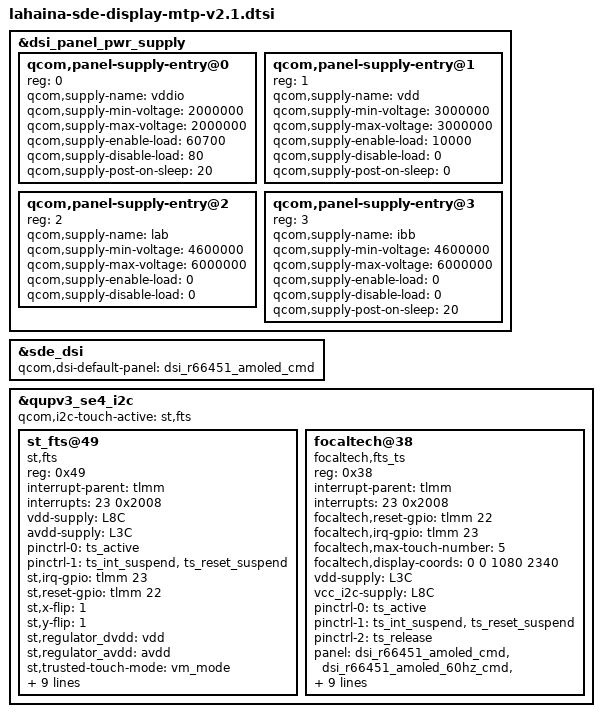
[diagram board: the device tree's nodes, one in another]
/*
 *Copyright (c) Qualcomm Technologies, Inc. and/or its subsidiaries.
 *SPDX-License-Identifier: BSD-3-Clause
*/

&dsi_panel_pwr_supply {
	#address-cells = <1>;
	#size-cells = <0>;

	qcom,panel-supply-entry@0 {
		reg = <0>;
		qcom,supply-name = "vddio";
		qcom,supply-min-voltage = <2000000>;
		qcom,supply-max-voltage = <2000000>;
		qcom,supply-enable-load = <60700>;
		qcom,supply-disable-load = <80>;
		qcom,supply-post-on-sleep = <20>;
	};

	qcom,panel-supply-entry@1 {
		reg = <1>;
		qcom,supply-name = "vdd";
		qcom,supply-min-voltage = <3000000>;
		qcom,supply-max-voltage = <3000000>;
		qcom,supply-enable-load = <10000>;
		qcom,supply-disable-load = <0>;
		qcom,supply-post-on-sleep = <0>;
	};

	qcom,panel-supply-entry@2 {
		reg = <2>;
		qcom,supply-name = "lab";
		qcom,supply-min-voltage = <4600000>;
		qcom,supply-max-voltage = <6000000>;
		qcom,supply-enable-load = <0>;
		qcom,supply-disable-load = <0>;
	};

	qcom,panel-supply-entry@3 {
		reg = <3>;
		qcom,supply-name = "ibb";
		qcom,supply-min-voltage = <4600000>;
		qcom,supply-max-voltage = <6000000>;
		qcom,supply-enable-load = <0>;
		qcom,supply-disable-load = <0>;
		qcom,supply-post-on-sleep = <20>;
	};
};

&sde_dsi {
	qcom,dsi-default-panel = <&dsi_r66451_amoled_cmd>;
};

&qupv3_se4_i2c {
	#address-cells = <1>;
	#size-cells = <0>;

	status = "ok";
	qcom,i2c-touch-active = "st,fts";

	st_fts@49 {
		compatible = "st,fts";
		reg = <0x49>;
		interrupt-parent = <&tlmm>;
		interrupts = <23 0x2008>;
		vdd-supply = <&L8C>;
		avdd-supply = <&L3C>;
		pinctrl-names = "pmx_ts_active", "pmx_ts_suspend";
		pinctrl-0 = <&ts_active>;
		pinctrl-1 = <&ts_int_suspend &ts_reset_suspend>;
		st,irq-gpio = <&tlmm 23 0x2008>;
		st,reset-gpio = <&tlmm 22 0x00>;
		st,x-flip = <1>;
		st,y-flip = <1>;
		st,regulator_dvdd = "vdd";
		st,regulator_avdd = "avdd";
		st,trusted-touch-mode = "vm_mode";
		st,touch-environment = "pvm";
		st,trusted-touch-spi-irq = <566>;
		st,trusted-touch-io-bases = <0xF114000 0xF115000 0xF116000 0xF117000 0x990000 0x00910000>;
		st,trusted-touch-io-sizes = <0x1000 0x1000 0x1000 0x1000 0x1000 0x4000>;
		panel = <&dsi_sw43404_amoled_cmd &dsi_sw43404_amoled_video
			 &dsi_sw43404_amoled_fhd_plus_cmd>;
	};

	focaltech@38 {
		compatible = "focaltech,fts_ts";
		reg = <0x38>;
		interrupt-parent = <&tlmm>;
		interrupts = <23 0x2008>;
		focaltech,reset-gpio = <&tlmm 22 0x00>;
		focaltech,irq-gpio = <&tlmm 23 0x2008>;
		focaltech,max-touch-number = <5>;
		focaltech,display-coords = <0 0 1080 2340>;

		vdd-supply = <&L3C>;
		vcc_i2c-supply = <&L8C>;

		pinctrl-names = "pmx_ts_active", "pmx_ts_suspend","pmx_ts_release";
		pinctrl-0 = <&ts_active>;
		pinctrl-1 = <&ts_int_suspend &ts_reset_suspend>;
		pinctrl-2 = <&ts_release>;

		panel = <&dsi_r66451_amoled_cmd
			 &dsi_r66451_amoled_60hz_cmd
			 &dsi_r66451_amoled_video &dsi_r66451_amoled_144hz_cmd>;

		focaltech,trusted-touch-mode = "vm_mode";
		focaltech,touch-environment = "pvm";
		focaltech,trusted-touch-spi-irq = <566>;
		focaltech,trusted-touch-io-bases = <0xF114000 0xF115000 0xF116000 0xF117000 0x990000 0x00910000>;
		focaltech,trusted-touch-io-sizes = <0x1000 0x1000 0x1000 0x1000 0x1000 0x4000>;
	};
};
